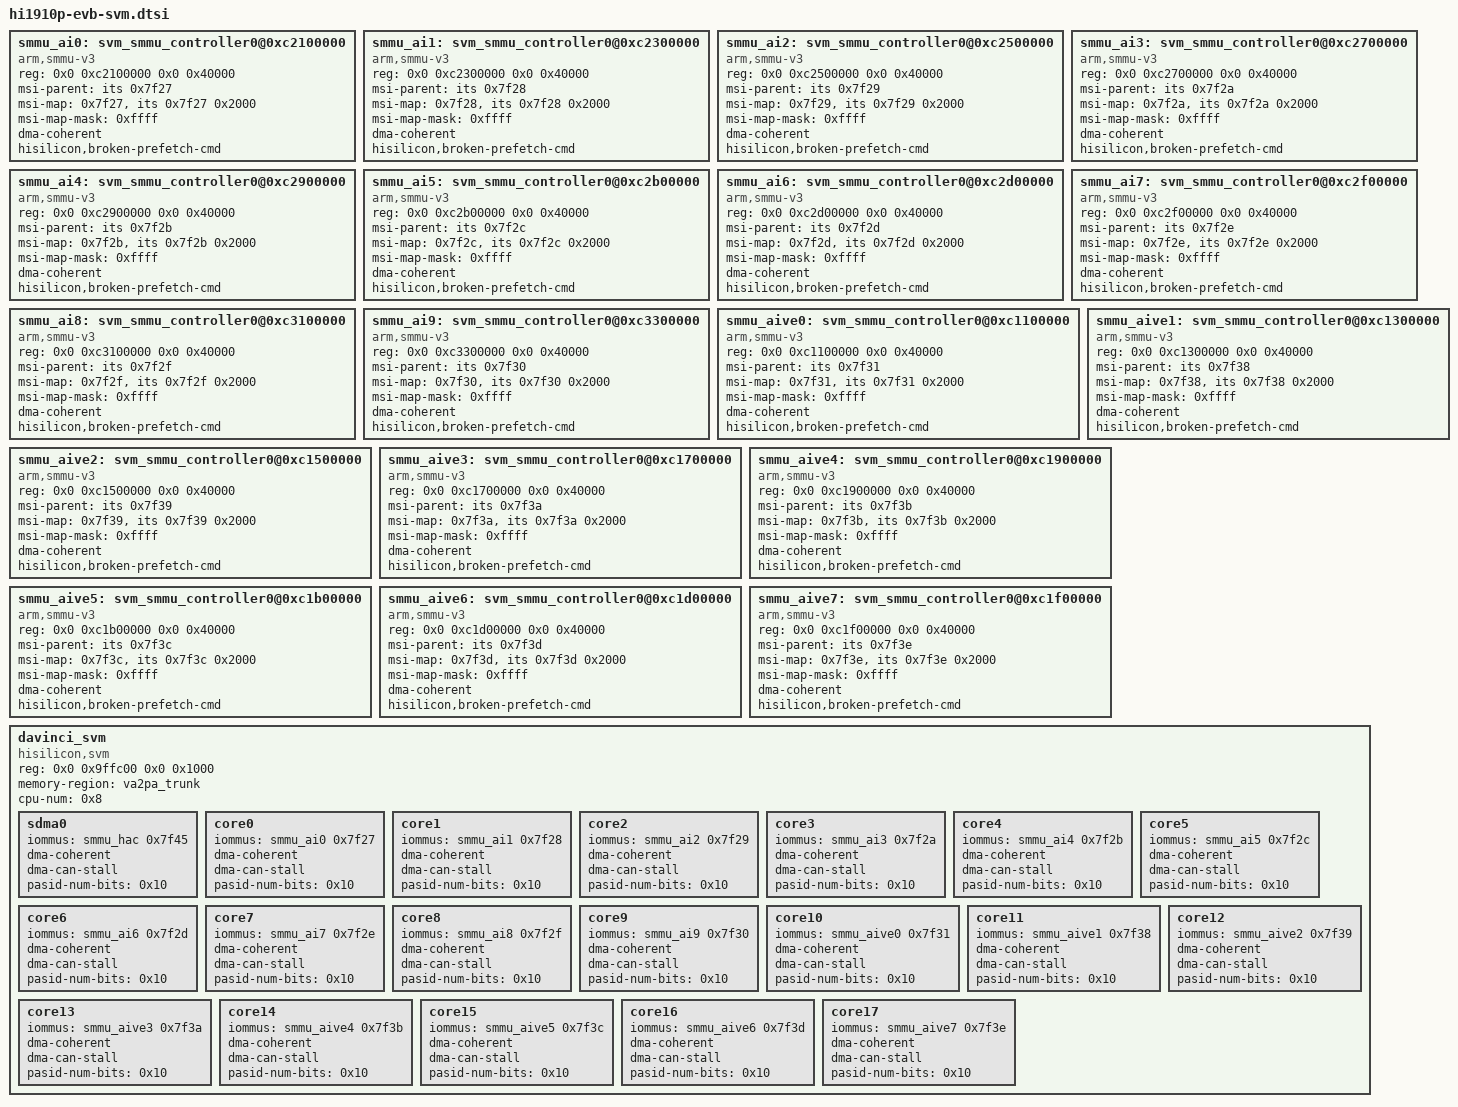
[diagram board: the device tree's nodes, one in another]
	smmu_ai0: svm_smmu_controller0@0xc2100000 {
		compatible = "arm,smmu-v3";
		reg = <0x0 0xc2100000 0x0 0x40000>;
		#iommu-cells = <0x1>;
		msi-parent = <&its 0x7f27>;
		msi-map = <0x7f27 &its 0x7f27 0x2000>;
		msi-map-mask = <0xffff>;
		dma-coherent;
		hisilicon,broken-prefetch-cmd;
	};

	smmu_ai1: svm_smmu_controller0@0xc2300000 {
		compatible = "arm,smmu-v3";
		reg = <0x0 0xc2300000 0x0 0x40000>;
		#iommu-cells = <0x1>;
		msi-parent = <&its 0x7f28>;
		msi-map = <0x7f28 &its 0x7f28 0x2000>;
		msi-map-mask = <0xffff>;
		dma-coherent;
		hisilicon,broken-prefetch-cmd;
	};

	smmu_ai2: svm_smmu_controller0@0xc2500000 {
		compatible = "arm,smmu-v3";
		reg = <0x0 0xc2500000 0x0 0x40000>;
		#iommu-cells = <0x1>;
		msi-parent = <&its 0x7f29>;
		msi-map = <0x7f29 &its 0x7f29 0x2000>;
		msi-map-mask = <0xffff>;
		dma-coherent;
		hisilicon,broken-prefetch-cmd;
	};

	smmu_ai3: svm_smmu_controller0@0xc2700000 {
		compatible = "arm,smmu-v3";
		reg = <0x0 0xc2700000 0x0 0x40000>;
		#iommu-cells = <0x1>;
		msi-parent = <&its 0x7f2a>;
		msi-map = <0x7f2a &its 0x7f2a 0x2000>;
		msi-map-mask = <0xffff>;
		dma-coherent;
		hisilicon,broken-prefetch-cmd;
	};

	smmu_ai4: svm_smmu_controller0@0xc2900000 {
		compatible = "arm,smmu-v3";
		reg = <0x0 0xc2900000 0x0 0x40000>;
		#iommu-cells = <0x1>;
		msi-parent = <&its 0x7f2b>;
		msi-map = <0x7f2b &its 0x7f2b 0x2000>;
		msi-map-mask = <0xffff>;
		dma-coherent;
		hisilicon,broken-prefetch-cmd;
	};

	smmu_ai5: svm_smmu_controller0@0xc2b00000 {
		compatible = "arm,smmu-v3";
		reg = <0x0 0xc2b00000 0x0 0x40000>;
		#iommu-cells = <0x1>;
		msi-parent = <&its 0x7f2c>;
		msi-map = <0x7f2c &its 0x7f2c 0x2000>;
		msi-map-mask = <0xffff>;
		dma-coherent;
		hisilicon,broken-prefetch-cmd;
	};

	smmu_ai6: svm_smmu_controller0@0xc2d00000 {
		compatible = "arm,smmu-v3";
		reg = <0x0 0xc2d00000 0x0 0x40000>;
		#iommu-cells = <0x1>;
		msi-parent = <&its 0x7f2d>;
		msi-map = <0x7f2d &its 0x7f2d 0x2000>;
		msi-map-mask = <0xffff>;
		dma-coherent;
		hisilicon,broken-prefetch-cmd;
	};

	smmu_ai7: svm_smmu_controller0@0xc2f00000 {
		compatible = "arm,smmu-v3";
		reg = <0x0 0xc2f00000 0x0 0x40000>;
		#iommu-cells = <0x1>;
		msi-parent = <&its 0x7f2e>;
		msi-map = <0x7f2e &its 0x7f2e 0x2000>;
		msi-map-mask = <0xffff>;
		dma-coherent;
		hisilicon,broken-prefetch-cmd;
	};

	smmu_ai8: svm_smmu_controller0@0xc3100000 {
		compatible = "arm,smmu-v3";
		reg = <0x0 0xc3100000 0x0 0x40000>;
		#iommu-cells = <0x1>;
		msi-parent = <&its 0x7f2f>;
		msi-map = <0x7f2f &its 0x7f2f 0x2000>;
		msi-map-mask = <0xffff>;
		dma-coherent;
		hisilicon,broken-prefetch-cmd;
	};

	smmu_ai9: svm_smmu_controller0@0xc3300000 {
		compatible = "arm,smmu-v3";
		reg = <0x0 0xc3300000 0x0 0x40000>;
		#iommu-cells = <0x1>;
		msi-parent = <&its 0x7f30>;
		msi-map = <0x7f30 &its 0x7f30 0x2000>;
		msi-map-mask = <0xffff>;
		dma-coherent;
		hisilicon,broken-prefetch-cmd;
	};
	smmu_aive0: svm_smmu_controller0@0xc1100000 {
		compatible = "arm,smmu-v3";
		reg = <0x0 0xc1100000 0x0 0x40000>;
		#iommu-cells = <0x1>;
		msi-parent = <&its 0x7f31>;
		msi-map = <0x7f31 &its 0x7f31 0x2000>;
		msi-map-mask = <0xffff>;
		dma-coherent;
		hisilicon,broken-prefetch-cmd;
	};

	smmu_aive1: svm_smmu_controller0@0xc1300000 {
		compatible = "arm,smmu-v3";
		reg = <0x0 0xc1300000 0x0 0x40000>;
		#iommu-cells = <0x1>;
		msi-parent = <&its 0x7f38>;
		msi-map = <0x7f38 &its 0x7f38 0x2000>;
		msi-map-mask = <0xffff>;
		dma-coherent;
		hisilicon,broken-prefetch-cmd;
	};

	smmu_aive2: svm_smmu_controller0@0xc1500000 {
		compatible = "arm,smmu-v3";
		reg = <0x0 0xc1500000 0x0 0x40000>;
		#iommu-cells = <0x1>;
		msi-parent = <&its 0x7f39>;
		msi-map = <0x7f39 &its 0x7f39 0x2000>;
		msi-map-mask = <0xffff>;
		dma-coherent;
		hisilicon,broken-prefetch-cmd;
	};

	smmu_aive3: svm_smmu_controller0@0xc1700000 {
		compatible = "arm,smmu-v3";
		reg = <0x0 0xc1700000 0x0 0x40000>;
		#iommu-cells = <0x1>;
		msi-parent = <&its 0x7f3a>;
		msi-map = <0x7f3a &its 0x7f3a 0x2000>;
		msi-map-mask = <0xffff>;
		dma-coherent;
		hisilicon,broken-prefetch-cmd;
	};

	smmu_aive4: svm_smmu_controller0@0xc1900000 {
		compatible = "arm,smmu-v3";
		reg = <0x0 0xc1900000 0x0 0x40000>;
		#iommu-cells = <0x1>;
		msi-parent = <&its 0x7f3b>;
		msi-map = <0x7f3b &its 0x7f3b 0x2000>;
		msi-map-mask = <0xffff>;
		dma-coherent;
		hisilicon,broken-prefetch-cmd;
	};

	smmu_aive5: svm_smmu_controller0@0xc1b00000 {
		compatible = "arm,smmu-v3";
		reg = <0x0 0xc1b00000 0x0 0x40000>;
		#iommu-cells = <0x1>;
		msi-parent = <&its 0x7f3c>;
		msi-map = <0x7f3c &its 0x7f3c 0x2000>;
		msi-map-mask = <0xffff>;
		dma-coherent;
		hisilicon,broken-prefetch-cmd;
	};

	smmu_aive6: svm_smmu_controller0@0xc1d00000 {
		compatible = "arm,smmu-v3";
		reg = <0x0 0xc1d00000 0x0 0x40000>;
		#iommu-cells = <0x1>;
		msi-parent = <&its 0x7f3d>;
		msi-map = <0x7f3d &its 0x7f3d 0x2000>;
		msi-map-mask = <0xffff>;
		dma-coherent;
		hisilicon,broken-prefetch-cmd;
	};

	smmu_aive7: svm_smmu_controller0@0xc1f00000 {
		compatible = "arm,smmu-v3";
		reg = <0x0 0xc1f00000 0x0 0x40000>;
		#iommu-cells = <0x1>;
		msi-parent = <&its 0x7f3e>;
		msi-map = <0x7f3e &its 0x7f3e 0x2000>;
		msi-map-mask = <0xffff>;
		dma-coherent;
		hisilicon,broken-prefetch-cmd;
	};


	davinci_svm {
		compatible = "hisilicon,svm";
		reg = <0x0 0x9ffc00 0x0 0x1000>;
		memory-region = <&va2pa_trunk>;
		ranges;
		#size-cells = <0x2>;
		#address-cells = <0x2>;
		cpu-num = <0x8>;

		sdma0 {
			iommus = <&smmu_hac 0x7f45>;
			dma-coherent;
			dma-can-stall;
			pasid-num-bits = <0x10>;
		};

		core0 {
			iommus = <&smmu_ai0 0x7f27>;
			dma-coherent;
			dma-can-stall;
			pasid-num-bits = <0x10>;
		};

		core1 {
			iommus = <&smmu_ai1 0x7f28>;
			dma-coherent;
			dma-can-stall;
			pasid-num-bits = <0x10>;
		};
			
		core2 {
			iommus = <&smmu_ai2 0x7f29>;
			dma-coherent;
			dma-can-stall;
			pasid-num-bits = <0x10>;
		};

		core3 {
			iommus = <&smmu_ai3 0x7f2a>;
			dma-coherent;
			dma-can-stall;
			pasid-num-bits = <0x10>;
		};

			core4 {
			iommus = <&smmu_ai4 0x7f2b>;
			dma-coherent;
			dma-can-stall;
			pasid-num-bits = <0x10>;
		};

		core5 {
			iommus = <&smmu_ai5 0x7f2c>;
			dma-coherent;
			dma-can-stall;
			pasid-num-bits = <0x10>;
		};

			core6 {
			iommus = <&smmu_ai6 0x7f2d>;
			dma-coherent;
			dma-can-stall;
			pasid-num-bits = <0x10>;
		};

		core7 {
			iommus = <&smmu_ai7 0x7f2e>;
			dma-coherent;
			dma-can-stall;
			pasid-num-bits = <0x10>;
		};

			core8 {
			iommus = <&smmu_ai8 0x7f2f>;
			dma-coherent;
			dma-can-stall;
			pasid-num-bits = <0x10>;
		};

		core9 {
			iommus = <&smmu_ai9 0x7f30>;
			dma-coherent;
			dma-can-stall;
			pasid-num-bits = <0x10>;
		};

			core10 {
			iommus = <&smmu_aive0 0x7f31>;
			dma-coherent;
			dma-can-stall;
			pasid-num-bits = <0x10>;
		};

		core11 {
			iommus = <&smmu_aive1 0x7f38>;
			dma-coherent;
			dma-can-stall;
			pasid-num-bits = <0x10>;
		};

			core12 {
			iommus = <&smmu_aive2 0x7f39>;
			dma-coherent;
			dma-can-stall;
			pasid-num-bits = <0x10>;
		};

		core13 {
			iommus = <&smmu_aive3 0x7f3a>;
			dma-coherent;
			dma-can-stall;
			pasid-num-bits = <0x10>;
		};

			core14 {
			iommus = <&smmu_aive4 0x7f3b>;
			dma-coherent;
			dma-can-stall;
			pasid-num-bits = <0x10>;
		};

		core15 {
			iommus = <&smmu_aive5 0x7f3c>;
			dma-coherent;
			dma-can-stall;
			pasid-num-bits = <0x10>;
		};

			core16 {
			iommus = <&smmu_aive6 0x7f3d>;
			dma-coherent;
			dma-can-stall;
			pasid-num-bits = <0x10>;
		};

		core17 {
			iommus = <&smmu_aive7 0x7f3e>;
			dma-coherent;
			dma-can-stall;
			pasid-num-bits = <0x10>;
		};
	};
	


